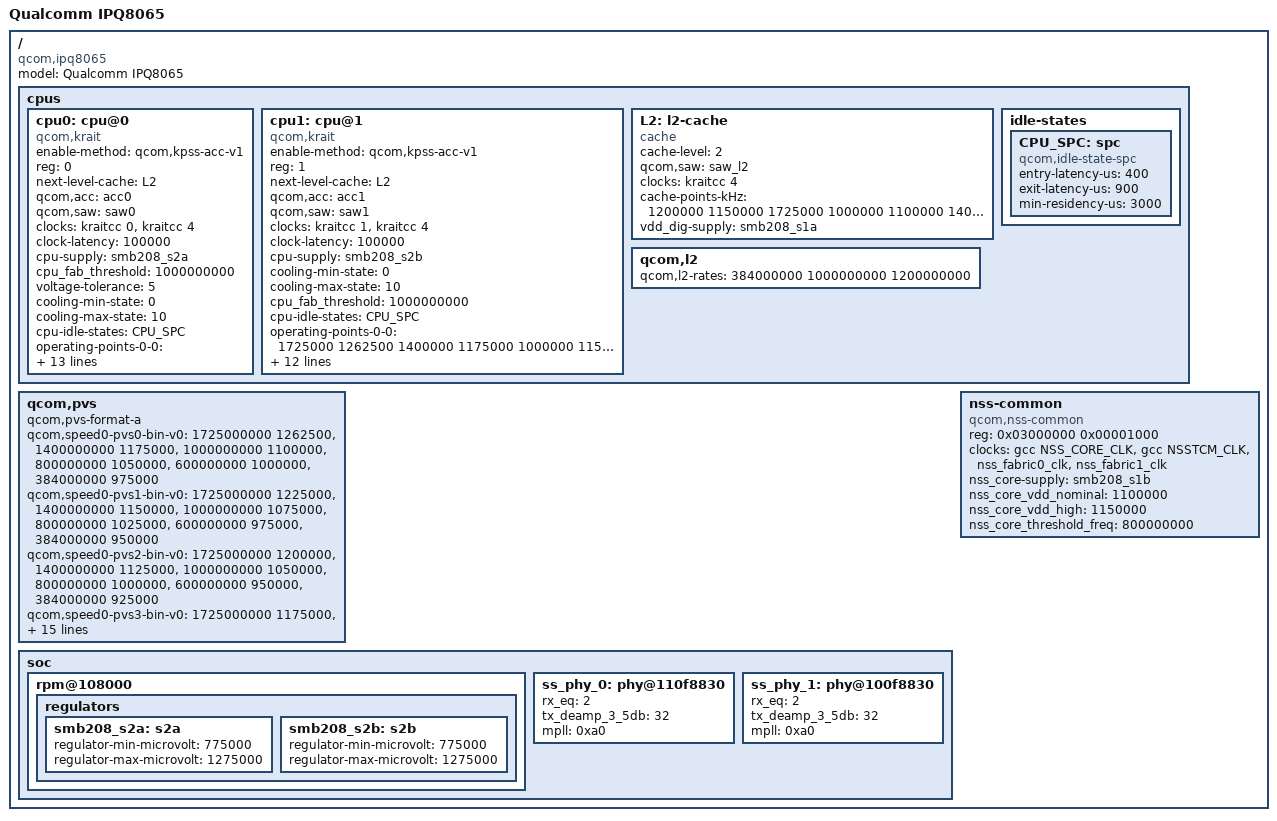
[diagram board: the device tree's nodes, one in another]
#include "qcom-ipq8064.dtsi"

/ {
	model = "Qualcomm IPQ8065";
	compatible = "qcom,ipq8065", "qcom,ipq8064";

	cpus {
		#address-cells = <1>;
		#size-cells = <0>;

		cpu0: cpu@0 {
			compatible = "qcom,krait";
			enable-method = "qcom,kpss-acc-v1";
			device_type = "cpu";
			reg = <0>;
			next-level-cache = <&L2>;
			qcom,acc = <&acc0>;
			qcom,saw = <&saw0>;
			clocks = <&kraitcc 0>, <&kraitcc 4>;
			clock-names = "cpu", "l2";
			clock-latency = <100000>;
			cpu-supply = <&smb208_s2a>;
			cpu_fab_threshold = <1000000000>;
			voltage-tolerance = <5>;
			cooling-min-state = <0>;
			cooling-max-state = <10>;
			#cooling-cells = <2>;
			cpu-idle-states = <&CPU_SPC>;

			operating-points-0-0 = <
				/* kHz      uV */
				1725000 1262500
				1400000 1175000
				1000000 1150000
				 800000 1050000
				 600000 1000000
 				 384000 975000
 			>;
			operating-points-0-1 = <
				/* kHz      uV */
				1725000 1225000
				1400000 1175000
				1000000 1075000
				 800000 1025000
				 600000  975000
				 384000  925000
			>;

			operating-points-0-2 = <
				/* kHz      uV */
				1725000 1200000
				1400000 1125000
				1000000 1050000
				 800000  1000000
				 600000  950000
				 384000  925000
			>;
			operating-points-0-3 = <
				/* kHz      uV */
				1725000 1175000
				1400000 1100000
				1000000 1025000
				 800000 975000
				 600000 925000
				 384000 900000
			>;

			operating-points-0-4 = <
				/* kHz      uV */
				1725000 1150000
				1400000 1075000
				1000000 1000000
				 800000 950000
				 600000 900000
				 384000 875000
			>;

			operating-points-0-5 = <
				/* kHz      uV */
				1725000 1100000
				1400000 1025000
				1000000 950000
				 800000 900000
				 600000 850000
				 384000 825000
			>;

			operating-points-0-6 = <
				/* kHz      uV */
				1725000 1050000
				1400000 975000
				1000000 900000
				 800000 850000
				 600000 800000
				 384000 775000
			>;
		};

		cpu1: cpu@1 {
			compatible = "qcom,krait";
			enable-method = "qcom,kpss-acc-v1";
			device_type = "cpu";
			reg = <1>;
			next-level-cache = <&L2>;
			qcom,acc = <&acc1>;
			qcom,saw = <&saw1>;
			clocks = <&kraitcc 1>, <&kraitcc 4>;
			clock-names = "cpu", "l2";
			clock-latency = <100000>;
			cpu-supply = <&smb208_s2b>;
			cooling-min-state = <0>;
			cooling-max-state = <10>;
			#cooling-cells = <2>;
			cpu_fab_threshold = <1000000000>;
			cpu-idle-states = <&CPU_SPC>;

			operating-points-0-0 = <
				/* kHz      uV */
				1725000 1262500
				1400000 1175000
				1000000 1150000
				 800000 1050000
				 600000 1000000
 				 384000 975000
 			>;
			operating-points-0-1 = <
				/* kHz      uV */
				1725000 1225000
				1400000 1175000
				1000000 1075000
				 800000 1025000
				 600000  975000
				 384000  925000
			>;

			operating-points-0-2 = <
				/* kHz      uV */
				1725000 1200000
				1400000 1125000
				1000000 1050000
				 800000  1000000
				 600000  950000
				 384000  925000
			>;
			operating-points-0-3 = <
				/* kHz      uV */
				1725000 1175000
				1400000 1100000
				1000000 1025000
				 800000 975000
				 600000 925000
				 384000 900000
			>;

			operating-points-0-4 = <
				/* kHz      uV */
				1725000 1150000
				1400000 1075000
				1000000 1000000
				 800000 950000
				 600000 900000
				 384000 875000
			>;

			operating-points-0-5 = <
				/* kHz      uV */
				1725000 1100000
				1400000 1025000
				1000000 950000
				 800000 900000
				 600000 850000
				 384000 825000
			>;

			operating-points-0-6 = <
				/* kHz      uV */
				1725000 1050000
				1400000 975000
				1000000 900000
				 800000 850000
				 600000 800000
				 384000 775000
			>;
		};

		L2: l2-cache {
			compatible = "cache";
			cache-level = <2>;
			qcom,saw = <&saw_l2>;
			clocks = <&kraitcc 4>;
			clock-names = "cache";
			cache-points-kHz = <
				/* kHz    uV    CPU kHz */
				1200000 1150000 1725000
				1000000 1100000 1400000
				1000000 1100000 1200000
				1000000 1100000  600000
				 384000 1100000  384000
			>;
			vdd_dig-supply = <&smb208_s1a>;
		};

		qcom,l2 {
			qcom,l2-rates = <384000000 1000000000 1200000000>;
		};

		idle-states {
			CPU_SPC: spc {
				compatible = "qcom,idle-state-spc",
						"arm,idle-state";
				entry-latency-us = <400>;
				exit-latency-us = <900>;
				min-residency-us = <3000>;
			};
		};
	};


	qcom,pvs {
		qcom,pvs-format-a;
		qcom,speed0-pvs0-bin-v0 =
			< 1725000000 1262500 >,
			< 1400000000 1175000 >,
			< 1000000000 1100000 >,
			 < 800000000 1050000 >,
			 < 600000000 1000000 >,
			 < 384000000 975000 >;
		qcom,speed0-pvs1-bin-v0 =
			< 1725000000 1225000 >,
			< 1400000000 1150000 >,
			< 1000000000 1075000 >,
			 < 800000000 1025000 >,
			 < 600000000 975000 >,
			 < 384000000 950000 >;
		qcom,speed0-pvs2-bin-v0 =
			< 1725000000 1200000 >,
			< 1400000000 1125000 >,
			< 1000000000 1050000 >,
			 < 800000000 1000000 >,
			 < 600000000 950000 >,
			 < 384000000 925000 >;
		qcom,speed0-pvs3-bin-v0 =
			< 1725000000 1175000 >,
			< 1400000000 1100000 >,
			< 1000000000 1025000 >,
			 < 800000000 975000 >,
			 < 600000000 925000 >,
			 < 384000000 900000 >;
		qcom,speed0-pvs4-bin-v0 =
			< 1725000000 1150000 >,
			< 1400000000 1075000 >,
			< 1000000000 1000000 >,
			 < 800000000 950000 >,
			 < 600000000 900000 >,
			 < 384000000 875000 >;
		qcom,speed0-pvs5-bin-v0 =
			< 1725000000 1100000 >,
			< 1400000000 1025000 >,
			< 1000000000 950000 >,
			 < 800000000 900000 >,
			 < 600000000 850000 >,
			 < 384000000 825000 >;
		qcom,speed0-pvs6-bin-v0 =
			< 1725000000 1050000 >,
			< 1400000000 975000 >,
			< 1000000000 900000 >,
			 < 800000000 850000 >,
			 < 600000000 800000 >,
			 < 384000000 775000 >;
	};

	soc: soc {

		rpm@108000 {

			regulators {

				smb208_s2a: s2a {
					regulator-min-microvolt = <775000>;
					regulator-max-microvolt = <1275000>;
				};

				smb208_s2b: s2b {
					regulator-min-microvolt = <775000>;
					regulator-max-microvolt = <1275000>;
				};
			};
		};

		ss_phy_0: phy@110f8830 {
			rx_eq = <2>;
			tx_deamp_3_5db = <32>;
			mpll = <0xa0>;
		};
		ss_phy_1: phy@100f8830 {
			rx_eq = <2>;
			tx_deamp_3_5db = <32>;
			mpll = <0xa0>;
		};

	};

	nss-common {
		compatible = "qcom,nss-common";
		reg = <0x03000000 0x00001000>;
		reg-names = "nss_fpb_base";
		clocks = <&gcc NSS_CORE_CLK>, <&gcc NSSTCM_CLK>,
			 <&nss_fabric0_clk>, <&nss_fabric1_clk>;
		clock-names = "nss-core-clk", "nss-tcm-clk", "nss-fab0-clk",
			      "nss-fab0-clk";
		nss_core-supply = <&smb208_s1b>;
		nss_core_vdd_nominal = <1100000>;
		nss_core_vdd_high = <1150000>;
		nss_core_threshold_freq = <800000000>;
	};

};
